# FM33L0XXD register map
File version: 1.0
CPU: SC000 r1p0, little endian, no MPU, FPU, 8 interrupt priority bits
Registers are 32-bit, read-write, reset 0x0 unless marked. A register's access mark holds for its fields unless they carry their own. Offsets are from the block's base; [hi:lo] are bit positions; {n}, {i} and the like mark numbered series.

## IWDT — IWDT module information
Base 0x40011400
0x00 IWDTSERV
  [31:0] IWDTSERV wo — IWDTSERV field description
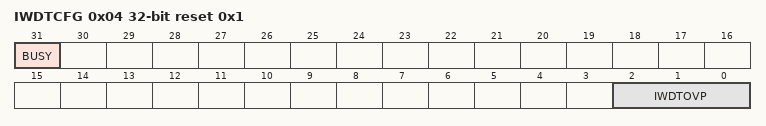
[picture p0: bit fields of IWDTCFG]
0x04 IWDTCFG reset 0x1
  [31] BUSY ro — BUSY field description
  [2:0] IWDTOVP — IWDTOVP field description
0x08 IWDTCNT
  [17:0] IWDTCNT ro — IWDTCNT field description

## LPTIM — LPTIM module information
Base 0x40013400
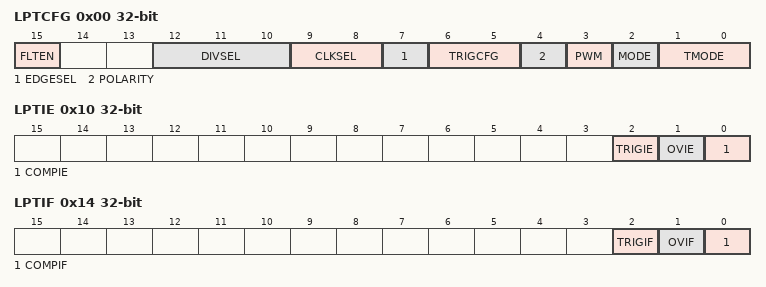
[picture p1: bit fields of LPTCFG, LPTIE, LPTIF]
0x00 LPTCFG
  [15] FLTEN — FLTEN field description
  [12:10] DIVSEL — DIVSEL field description
  [9:8] CLKSEL — CLKSEL field description
  [7] EDGESEL — EDGESEL field description
  [6:5] TRIGCFG — TRIGCFG field description
  [4] POLARITY — POLARITY field description
  [3] PWM — PWM field description
  [2] MODE — MODE field description
  [1:0] TMODE — TMODE field description
0x04 LPTCNT
  [15:0] CNT16 ro — CNT16 field description
0x08 LPTCMP
  [15:0] COMPAREREG — COMPARE_REG field description
0x0C LPTTARGET
  [15:0] TARGETREG — TARGET_REG field description
0x10 LPTIE
  [2] TRIGIE — TRIGIE field description
  [1] OVIE — OVIE field description
  [0] COMPIE — COMPIE field description
0x14 LPTIF
  [2] TRIGIF — TRIGIF field description
  [1] OVIF — OVIF field description
  [0] COMPIF — COMPIF field description
0x18 LPTCTRL
  [0] LPT16EN — LPT16EN field description

## LPUART0 — LPUART0 module information
Base 0x40010400
Same registers: LPUART1 0x40010800
0x00 LPURXD
  [7:0] RXBUF ro — RXBUF field description
0x04 LPUTXD
  [7:0] LPUTXD wo — LPUTXD field description
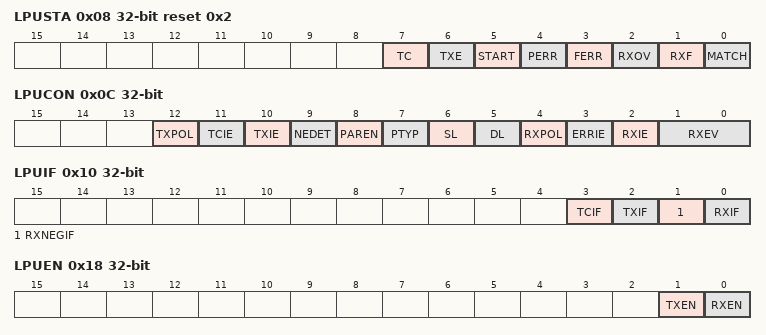
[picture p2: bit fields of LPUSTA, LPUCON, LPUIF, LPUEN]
0x08 LPUSTA reset 0x2
  [7] TC ro — TC field description
  [6] TXE ro — TXE field description
  [5] START — START field description
  [4] PERR — PERR field description
  [3] FERR — FERR field description
  [2] RXOV — RXOV field description
  [1] RXF ro — RXF field description
  [0] MATCH — MATCH field description
0x0C LPUCON
  [12] TXPOL — TXPOL field description
  [11] TCIE — TCIE field description
  [10] TXIE — TXIE field description
  [9] NEDET — NEDET field description
  [8] PAREN — PAREN field description
  [7] PTYP — PTYP field description
  [6] SL — SL field description
  [5] DL — DL field description
  [4] RXPOL — RXPOL field description
  [3] ERRIE — ERRIE field description
  [2] RXIE — RXIE field description
  [1:0] RXEV — RXEV field description
0x10 LPUIF
  [3] TCIF — TC_IF field description
  [2] TXIF — TXIF field description
  [1] RXNEGIF — RXNEGIF field description
  [0] RXIF — RXIF field description
0x14 LPUBAUD
  [2:0] BAUD — BAUD field description
0x18 LPUEN
  [1] TXEN — TXEN field description
  [0] RXEN — RXEN field description
0x1C COMPARE
  [7:0] COMPARE — COMPARE field description
0x20 MODU
  [11:0] MCTL — MCTL field description

## PMU — PMU module information
Base 0x40000100
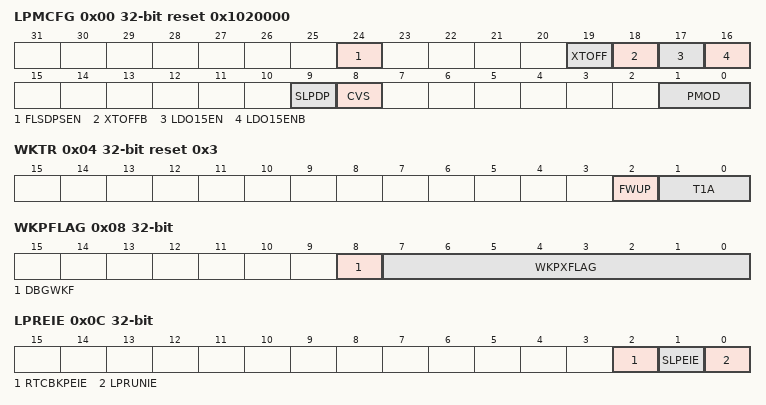
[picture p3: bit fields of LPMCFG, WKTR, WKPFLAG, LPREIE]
0x00 LPMCFG reset 0x1020000
  [24] FLSDPSEN ro — FLSDPSEN field description
  [19] XTOFF — XTOFF field description
  [18] XTOFFB ro — XTOFFB field description
  [17] LDO15EN ro — LDO15EN field description
  [16] LDO15ENB ro — LDO15EN_B field description
  [9] SLPDP — SLPDP field description
  [8] CVS — CVS field description
  [1:0] PMOD — PMOD field description
0x04 WKTR reset 0x3
  [2] FWUP — FWUP field description
  [1:0] T1A — T1A field description
0x08 WKPFLAG
  [8] DBGWKF — DBGWKF field description
  [7:0] WKPXFLAG — WKPX_FLAG field description
0x0C LPREIE
  [2] RTCBKPEIE — RTCBKPEIE field description
  [1] SLPEIE — SLPEIE field description
  [0] LPRUNIE — LPRUNIE field description
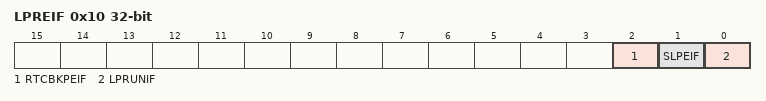
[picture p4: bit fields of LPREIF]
0x10 LPREIF
  [2] RTCBKPEIF — RTCBKPEIF field description
  [1] SLPEIF — SLPEIF field description
  [0] LPRUNIF — LPRUNIF field description

## RMU — RMU module information
Base 0x40000200
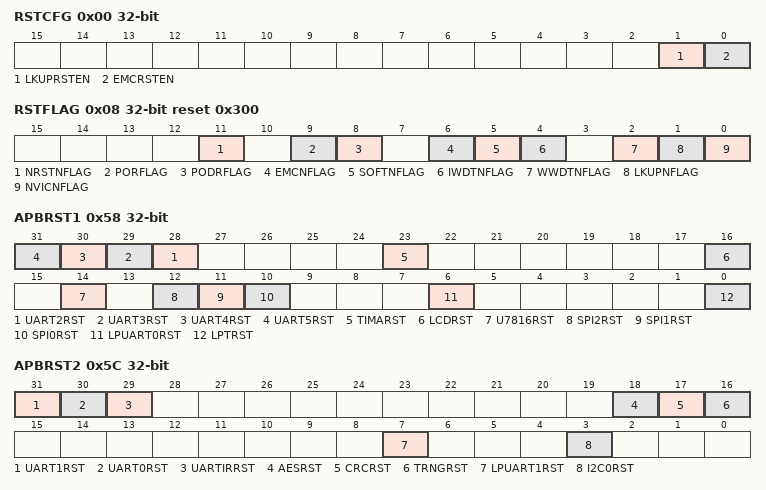
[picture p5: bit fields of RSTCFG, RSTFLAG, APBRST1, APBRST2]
0x00 RSTCFG
  [1] LKUPRSTEN — LKUPRST_EN field description
  [0] EMCRSTEN — EMCRST_EN field description
0x04 SOFTRST
  [31:0] SOFTRST wo — SOFTRST field description
0x08 RSTFLAG reset 0x300
  [11] NRSTNFLAG — NRSTN_FLAG field description
  [9] PORFLAG — POR_FLAG field description
  [8] PODRFLAG — PODR_FLAG field description
  [6] EMCNFLAG — EMCN_FLAG field description
  [5] SOFTNFLAG — SOFTN_FLAG field description
  [4] IWDTNFLAG — IWDTN_FLAG field description
  [2] WWDTNFLAG — WWDTN_FLAG field description
  [1] LKUPNFLAG — LKUPN_FLAG field description
  [0] NVICNFLAG — NVICN_FLAG field description
0x50 PERHRSTEN
  [31:0] PERHRSTEN wo — PERHRSTEN field description
0x54 AHBRST
  [0] DMARST — DMARST field description
0x58 APBRST1
  [n+26] UART{n}RST (n=2..5) — UART{n}RST field description
  [23] TIMARST — TIMARST field description
  [16] LCDRST — LCDRST field description
  [14] U7816RST — U7816RST field description
  [12] SPI2RST — SPI2RST field description
  [11] SPI1RST — SPI1RST field description
  [10] SPI0RST — SPI0RST field description
  [6] LPUART0RST — LPUART0RST field description
  [0] LPTRST — LPTRST field description
0x5C APBRST2
  [31] UART1RST — UART1RST field description
  [30] UART0RST — UART0RST field description
  [29] UARTIRRST — UARTIRRST field description
  [18] AESRST — AESRST field description
  [17] CRCRST — CRCRST field description
  [16] TRNGRST — TRNGRST field description
  [7] LPUART1RST — LPUART1RST field description
  [3] I2C0RST — I2C0RST field description
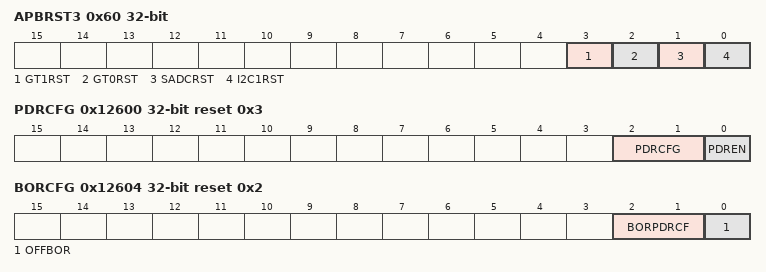
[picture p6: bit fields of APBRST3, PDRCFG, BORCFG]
0x60 APBRST3
  [3] GT1RST — GT1RST field description
  [2] GT0RST — GT0RST field description
  [1] SADCRST — SADCRST field description
  [0] I2C1RST — I2C1RST field description
0x12600 PDRCFG reset 0x3
  [2:1] PDRCFG — PDRCFG field description
  [0] PDREN — PDREN field description
0x12604 BORCFG reset 0x2
  [2:1] BORPDRCF G — BOR_PDRCF G field description
  [0] OFFBOR — OFF_BOR field description
